# PCIE_APPLICATION register map
Vendor: Texas Instruments
Peripheral module from a debugger description file (folder 66AK2G0x_66AK2G1x).
Registers are 32-bit, access not given, reset 0x0 unless marked. A register's access mark holds for its fields unless they carry their own. Offsets are as the file gives them; lines under a group give offsets from that group; [hi:lo] are bit positions; {n}, {i} and the like mark numbered series; 'fields as' and 'values as' point back to an identical list; <NAME> marks a mode.

## PCIE_APPLICATION
0x00 PCIE_PID ro reset 0x4E330900
  [31:0] REV — TI internal data. Identifies revision of peripheral.
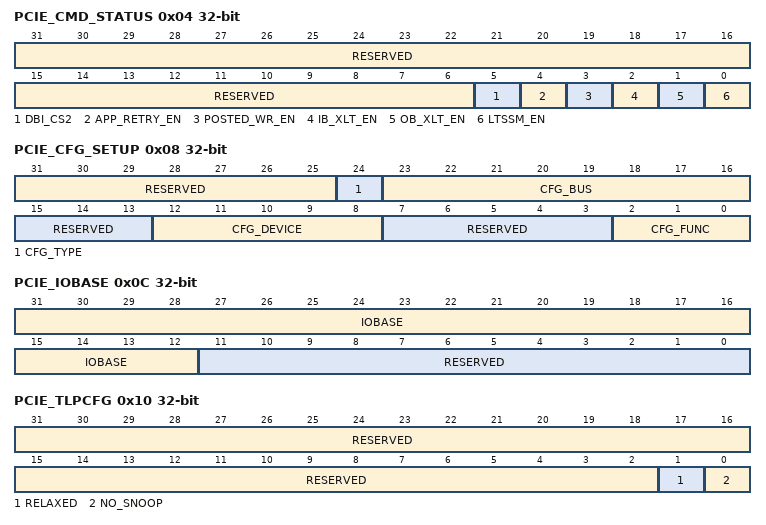
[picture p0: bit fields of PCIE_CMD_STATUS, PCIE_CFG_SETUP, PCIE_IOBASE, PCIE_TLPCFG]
0x04 PCIE_CMD_STATUS access per field
  [31:6] RESERVED ro — Reads return 0 and writes have no effect.
  [5] DBI_CS2 rw — Set to enable writing to BAR mask registers that are overlaid on BAR registers.
  [4] APP_RETRY_EN rw — Application request retry enable. This feature can be used if initialization can take longer than PCIe stipulated time frame.
  [3] POSTED_WR_EN rw — Posted write enable. Default is 0 with all internal bus master writes defaulting to non-posted.
  [2] IB_XLT_EN rw — Inbound address translation enable.
  [1] OB_XLT_EN rw — Outbound address translation enable.
  [0] LTSSM_EN rw — Link training enable.
0x08 PCIE_CFG_SETUP access per field
  [31:25] RESERVED ro — Reads return 0 and writes have no effect.
  [24] CFG_TYPE rw — Configuration type for outbound configuration accesses.
  [23:16] CFG_BUS rw — PCIe bus number for outbound configuration accesses (value = 0-FFh).
  [15:13] RESERVED ro — Reads return 0 and writes have no effect.
  [12:8] CFG_DEVICE rw — PCIe device number for outbound configuration accesses (value = 0-1Fh).
  [7:3] RESERVED ro — Reads return 0 and writes have no effect.
  [2:0] CFG_FUNC rw — PCIe function number for outbound configuration accesses (value = 0-7h).
0x0C PCIE_IOBASE access per field
  [31:12] IOBASE rw — Bits [31-12] of outgoing IO TLP (value = 0-FFFFFh). RC mode only.
  [11:0] RESERVED ro — Reads return 0 and writes have no effect.
0x10 PCIE_TLPCFG access per field
  [31:2] RESERVED ro — Reads return 0 and writes have no effect.
  [1] RELAXED rw — Enable relaxed ordering for all outgoing TLPs.
  [0] NO_SNOOP rw — Enable No Snoop attribute on all outgoing TLPs.
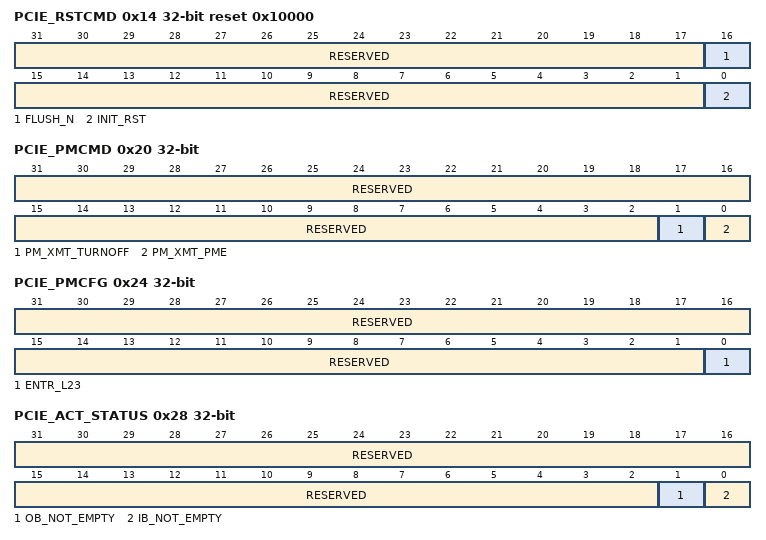
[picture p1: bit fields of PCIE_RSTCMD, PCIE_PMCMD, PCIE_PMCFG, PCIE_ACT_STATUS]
0x14 PCIE_RSTCMD reset 0x10000
  [31:17] RESERVED ro — Reads return 0 and writes have no effect.
  [16] FLUSH_N ro — Bridge flush status. Used to ensure no pending transactions prior to issuing warm reset.
  [15:1] RESERVED ro — Reads return 0 and writes have no effect.
  [0] INIT_RST — Write 1 to initiate a downstream hot reset sequence on downstream. (access W1S)
0x20 PCIE_PMCMD
  [31:2] RESERVED ro — Reads return 0 and writes have no effect.
  [1] PM_XMT_TURNOFF — Write 1 to transmit a PM_TURNOFF message. Reads 0. Applicable in RC mode only. (access W1S)
  [0] PM_XMT_PME — Write 1 to transmit a PM_PME message. Reads 0. Applicable to EP mode only. (access W1S)
0x24 PCIE_PMCFG access per field
  [31:1] RESERVED ro — Reads return 0 and writes have no effect.
  [0] ENTR_L23 rw — Write 1 to enable entry to L2/L3 ready state. Read to check L2/L3 entry readiness. Applicable to RC and EP.
0x28 PCIE_ACT_STATUS ro
  [31:2] RESERVED — Reads return 0 and writes have no effect.
  [1] OB_NOT_EMPTY
  [0] IB_NOT_EMPTY
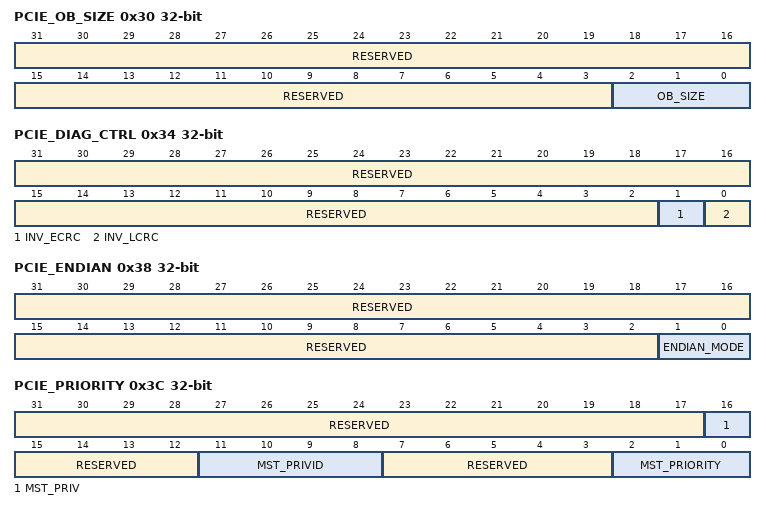
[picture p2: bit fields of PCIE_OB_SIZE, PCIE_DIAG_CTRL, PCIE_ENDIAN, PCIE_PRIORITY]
0x30 PCIE_OB_SIZE access per field
  [31:3] RESERVED ro — Reads return 0 and writes have no effect.
  [2:0] OB_SIZE rw — Set each outbound translation window size. Applicable to RC and EP.
0x34 PCIE_DIAG_CTRL access per field
  [31:2] RESERVED ro — Reads return 0 and writes have no effect.
  [1] INV_ECRC rw — Write 1 to force inversion of LSB of ECRC for the next one packet. It is self cleared when the ECRC error has been injected on one TLP.
  [0] INV_LCRC rw — Write 1 to force inversion of LSB of LCRC for the next one packet. It is self cleared when the LCRC error has been injected on one TLP.
0x38 PCIE_ENDIAN access per field
  [31:2] RESERVED ro — Reads return 0 and writes have no effect.
  [1:0] ENDIAN_MODE rw
0x3C PCIE_PRIORITY access per field
  [31:17] RESERVED ro — Reads return 0 and writes have no effect.
  [16] MST_PRIV rw — Master transaction mode. PCIe transaction needs to be in supervisor mode to access the device registers.
  [15:12] RESERVED ro — Reads return 0 and writes have no effect.
  [11:8] MST_PRIVID ro — Master PRIVID value on master transactions.
  [7:3] RESERVED ro — Reads return 0 and writes have no effect.
  [2:0] MST_PRIORITY rw — Priority level for each inbound transaction on the internal bus master port. 0 is the highest priority level and 7h is the lowest priority level.
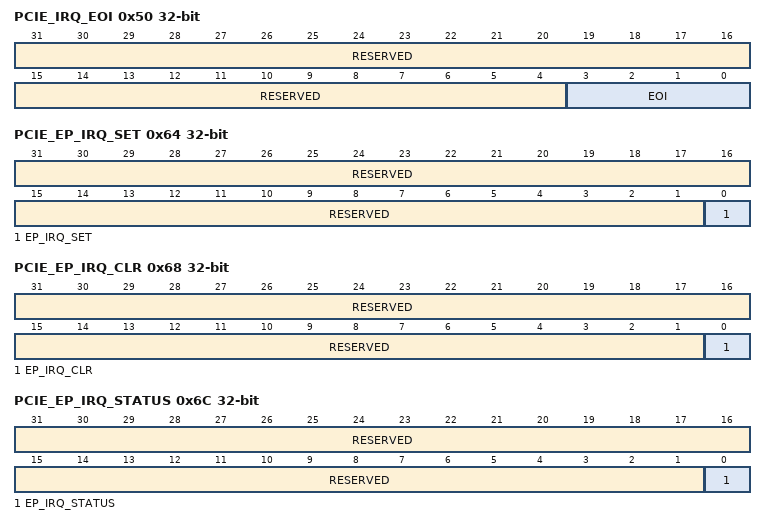
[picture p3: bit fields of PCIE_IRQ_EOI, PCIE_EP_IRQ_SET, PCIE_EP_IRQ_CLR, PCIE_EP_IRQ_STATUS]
0x50 PCIE_IRQ_EOI access per field
  [31:4] RESERVED ro — Reads return 0 and writes have no effect.
  [3:0] EOI wo — EOI for interrupts. Write the interrupt event number to indicate end-of-interrupt for the interrupt events. Write 0 to mark EOI for INTA, 1 for INTB and so on. Please see the for the interrupt event number.
0x54 PCIE_MSI_IRQ wo
  [31:0] MSI_IRQ — This register is written to by the remote device. Writes initiated by an EP over PCIe link that targetPCIE_BAR0 of the RC land to this register if the offset matches. EP should write MSI vector value to this register to generate corresponding MSI Interrupt, such as writing 0x0 to generate MSI_0 interrupt (with vector 0), writing 0x1F to generate MSI_7 interrupt (with vector 31).
0x64 PCIE_EP_IRQ_SET
  [31:1] RESERVED ro — Reads return 0 and writes have no effect.
  [0] EP_IRQ_SET — Write 1 to generate assert interrupt message. If MSI is disabled, legacy interrupt assert message will be generated. On read, a 1 indicates currently asserted interrupt. (access RW1S)
0x68 PCIE_EP_IRQ_CLR
  [31:1] RESERVED ro — Reads return 0 and writes have no effect.
  [0] EP_IRQ_CLR — Write 1 to generate deassert interrupt message. If MSI is disabled, legacy interrupt deassert message will be generated. On read, a 1 indicates currently asserted interrupt. (access RW1C)
0x6C PCIE_EP_IRQ_STATUS ro
  [31:1] RESERVED — Reads return 0 and writes have no effect.
  [0] EP_IRQ_STATUS — Indicates whether interrupt for function 0 is asserted or not.
{0x70+4i} PCIE_GPR{i} rw (i=0..3)
  [31:0] GENERIC{i} — Generic info field {i} (value = 0-FFFFFFFFh).
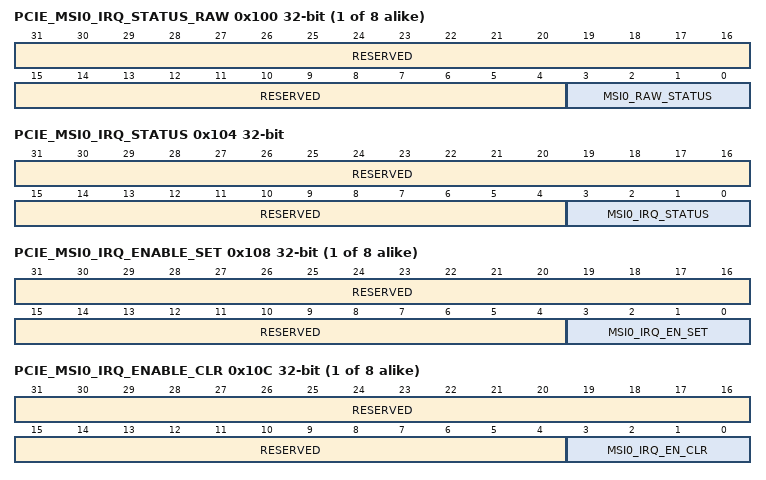
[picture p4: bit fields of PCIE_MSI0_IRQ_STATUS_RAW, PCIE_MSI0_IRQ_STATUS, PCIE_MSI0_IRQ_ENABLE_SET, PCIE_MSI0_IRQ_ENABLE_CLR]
{0x100+0x10*i} PCIE_MSI{i}_IRQ_STATUS_RAW (i=0..7)
  [31:4] RESERVED ro — Reads return 0 and writes have no effect.
  [3:0] MSI{i}_RAW_STATUS — Each bit indicates raw status of MSI vectors ({i+24}, {i+16}, {i+8}, {i}) associated with the bit. Typically, writes to this register are only done for debug purposes. (access RW1S)
0x104 PCIE_MSI0_IRQ_STATUS
  [31:4] RESERVED ro — Reads return 0 and writes have no effect.
  [3:0] MSI0_IRQ_STATUS — Each bit indicates status of MSI vector (24, 16, 8, 0) associated with the bit. Each of the bits can be written with 1 to clear the respective interrupt status bit. (access RW1C)
{0x108+0x10*i} PCIE_MSI{i}_IRQ_ENABLE_SET (i=0..7)
  [31:4] RESERVED ro — Reads return 0 and writes have no effect.
  [3:0] MSI{i}_IRQ_EN_SET — Each bit, when written to, enables the MSI interrupt ({i+24}, {i+16}, {i+8}, {i}) associated with the bit. (access RW1S)
{0x10C+0x10*i} PCIE_MSI{i}_IRQ_ENABLE_CLR (i=0..7)
  [31:4] RESERVED ro — Reads return 0 and writes have no effect.
  [3:0] MSI{i}_IRQ_EN_CLR — Each bit, when written to, disables the MSI interrupt ({i+24}, {i+16}, {i+8}, {i}) associated with the bit. (access RW1C)
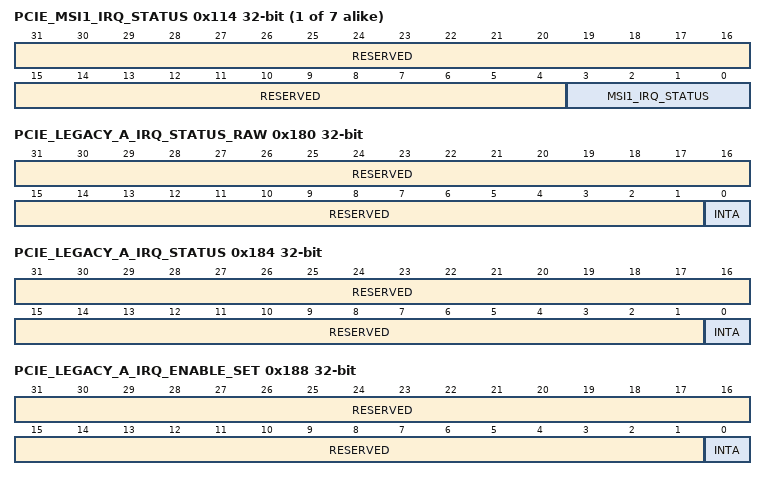
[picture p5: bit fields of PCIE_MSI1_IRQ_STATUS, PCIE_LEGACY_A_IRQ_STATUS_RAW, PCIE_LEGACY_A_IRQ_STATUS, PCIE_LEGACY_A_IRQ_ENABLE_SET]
{0x104+0x10*i} PCIE_MSI{i}_IRQ_STATUS (i=1..7)
  [31:4] RESERVED ro — Reads return 0 and writes have no effect.
  [3:0] MSI{i}_IRQ_STATUS — Each bit indicates status of MSI vector ({i+24}, {i+16}, {i+8}, {i}) associated with the bit. Each of the bits can be written with one to clear the respective interrupt status bit. (access RW1C)
0x180 PCIE_LEGACY_A_IRQ_STATUS_RAW
  [31:1] RESERVED ro — Reads return 0 and writes have no effect.
  [0] INTA — Legacy Interrupt A raw status. RC mode only. (access RW1S)
0x184 PCIE_LEGACY_A_IRQ_STATUS
  [31:1] RESERVED ro — Reads return 0 and writes have no effect.
  [0] INTA — Legacy Interrupt A status. Set when interrupt is active. Write one to clear the interrupt event. RC mode only. (access RW1C)
0x188 PCIE_LEGACY_A_IRQ_ENABLE_SET
  [31:1] RESERVED ro — Reads return 0 and writes have no effect.
  [0] INTA — Legacy Interrupt A enable. Set to enable the interrupt.On read: (access RW1S)
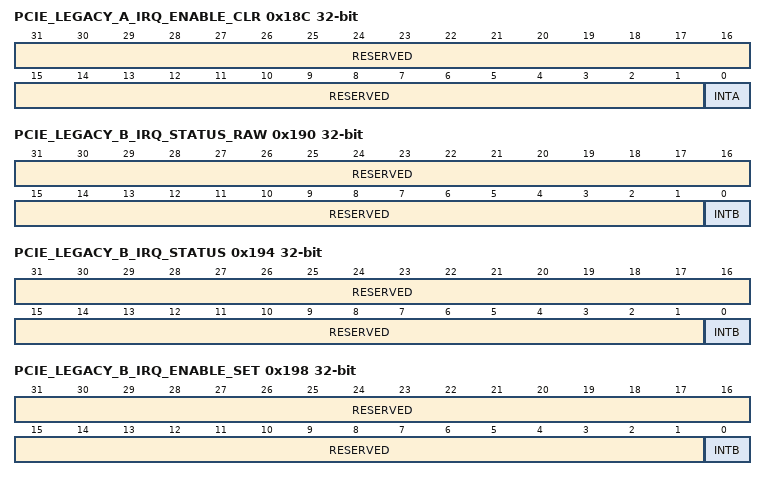
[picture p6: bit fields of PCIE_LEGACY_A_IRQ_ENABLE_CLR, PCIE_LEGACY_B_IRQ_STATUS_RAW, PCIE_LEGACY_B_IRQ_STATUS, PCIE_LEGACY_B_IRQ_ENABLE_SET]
0x18C PCIE_LEGACY_A_IRQ_ENABLE_CLR
  [31:1] RESERVED ro — Reads return 0 and writes have no effect.
  [0] INTA — Legacy Interrupt A disable. Set to disable the interrupt.On read: (access RW1C)
0x190 PCIE_LEGACY_B_IRQ_STATUS_RAW
  [31:1] RESERVED ro — Reads return 0 and writes have no effect.
  [0] INTB — Legacy Interrupt B raw status. RC mode only. (access RW1S)
0x194 PCIE_LEGACY_B_IRQ_STATUS
  [31:1] RESERVED ro — Reads return 0 and writes have no effect.
  [0] INTB — Legacy Interrupt B status. Set when interrupt is active. Write one to clear the interrupt event. RC mode only. (access RW1C)
0x198 PCIE_LEGACY_B_IRQ_ENABLE_SET
  [31:1] RESERVED ro — Reads return 0 and writes have no effect.
  [0] INTB — Legacy Interrupt B enable. Set to enable the interrupt.On read: (access RW1S)
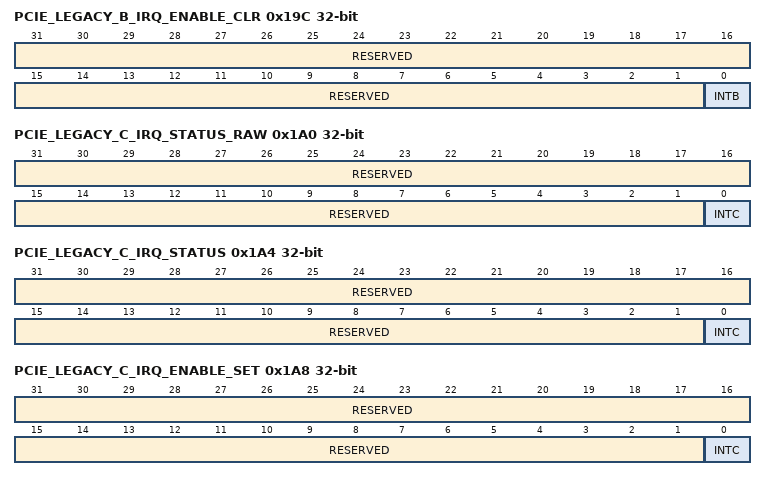
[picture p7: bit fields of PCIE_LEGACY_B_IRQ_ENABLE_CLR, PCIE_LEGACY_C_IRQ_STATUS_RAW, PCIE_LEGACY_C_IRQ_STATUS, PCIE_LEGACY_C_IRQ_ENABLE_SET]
0x19C PCIE_LEGACY_B_IRQ_ENABLE_CLR
  [31:1] RESERVED ro — Reads return 0 and writes have no effect.
  [0] INTB — Legacy Interrupt B disable. Set to disable the interrupt.On read: (access RW1C)
0x1A0 PCIE_LEGACY_C_IRQ_STATUS_RAW
  [31:1] RESERVED ro — Reads return 0 and writes have no effect.
  [0] INTC — Legacy Interrupt C raw status. RC mode only. (access RW1S)
0x1A4 PCIE_LEGACY_C_IRQ_STATUS
  [31:1] RESERVED ro — Reads return 0 and writes have no effect.
  [0] INTC — Legacy Interrupt C status. Set when interrupt is active. Write one to clear the interrupt event. RC mode only. (access RW1C)
0x1A8 PCIE_LEGACY_C_IRQ_ENABLE_SET
  [31:1] RESERVED ro — Reads return 0 and writes have no effect.
  [0] INTC — Legacy Interrupt C enable. Set to enable the interrupt.On read: (access RW1S)
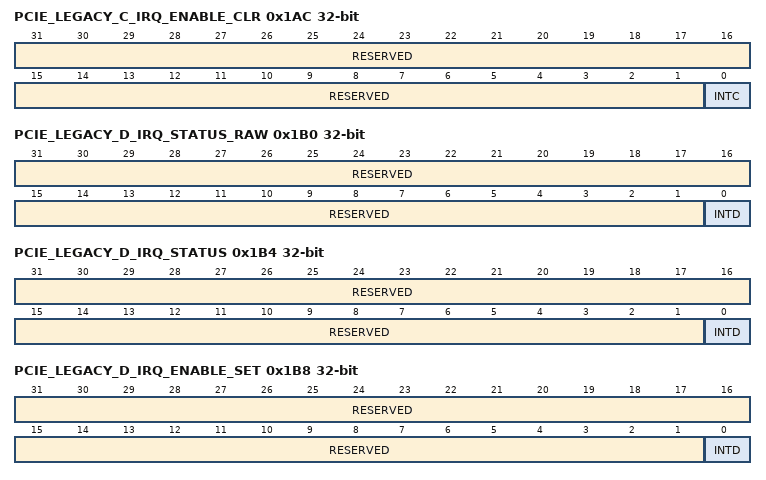
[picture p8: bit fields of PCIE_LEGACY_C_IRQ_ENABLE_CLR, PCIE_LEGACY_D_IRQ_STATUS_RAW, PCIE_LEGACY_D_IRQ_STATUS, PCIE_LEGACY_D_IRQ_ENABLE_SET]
0x1AC PCIE_LEGACY_C_IRQ_ENABLE_CLR
  [31:1] RESERVED ro — Reads return 0 and writes have no effect.
  [0] INTC — Legacy Interrupt C disable. Set to disable the interrupt.On read: (access RW1C)
0x1B0 PCIE_LEGACY_D_IRQ_STATUS_RAW
  [31:1] RESERVED ro — Reads return 0 and writes have no effect.
  [0] INTD — Legacy Interrupt D raw status. RC mode only. (access RW1S)
0x1B4 PCIE_LEGACY_D_IRQ_STATUS
  [31:1] RESERVED ro — Reads return 0 and writes have no effect.
  [0] INTD — Legacy Interrupt D status. Set when interrupt is active. Write one to clear the interrupt event. RC mode only. (access RW1C)
0x1B8 PCIE_LEGACY_D_IRQ_ENABLE_SET
  [31:1] RESERVED ro — Reads return 0 and writes have no effect.
  [0] INTD — Legacy Interrupt D enable. Set to enable the interrupt.On read: (access RW1S)
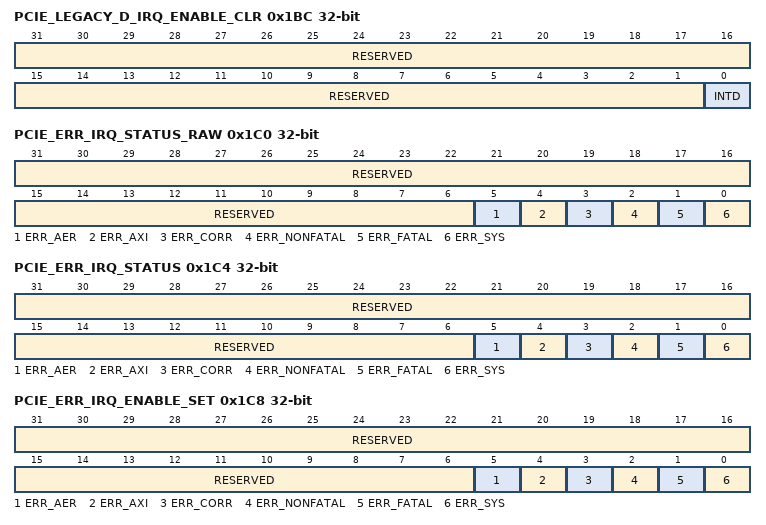
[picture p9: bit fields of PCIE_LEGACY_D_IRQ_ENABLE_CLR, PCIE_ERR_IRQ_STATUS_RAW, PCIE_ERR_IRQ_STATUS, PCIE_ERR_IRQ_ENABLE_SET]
0x1BC PCIE_LEGACY_D_IRQ_ENABLE_CLR
  [31:1] RESERVED ro — Reads return 0 and writes have no effect.
  [0] INTD — Legacy Interrupt D disable. Set to disable the interrupt.On read: (access RW1C)
0x1C0 PCIE_ERR_IRQ_STATUS_RAW
  [31:6] RESERVED ro — Reads return 0 and writes have no effect.
  [5] ERR_AER — ECRC error raw status. (access RW1S)
  [4] ERR_AXI — AXI tag lookup fatal error raw status. (access RW1S)
  [3] ERR_CORR — Correctable error raw status. (access RW1S)
  [2] ERR_NONFATAL — Nonfatal error raw status. (access RW1S)
  [1] ERR_FATAL — Fatal error raw status. (access RW1S)
  [0] ERR_SYS — System error (fatal, nonfatal or correctable error) raw status. (access RW1S)
0x1C4 PCIE_ERR_IRQ_STATUS
  [31:6] RESERVED ro — Reads return 0 and writes have no effect.
  [5] ERR_AER — ECRC error status. (access RW1C)
  [4] ERR_AXI — AXI tag lookup fatal error. (access RW1C)
  [3] ERR_CORR — Correctable error status. (access RW1C)
  [2] ERR_NONFATAL — Nonfatal error status. (access RW1C)
  [1] ERR_FATAL — Fatal error status. (access RW1C)
  [0] ERR_SYS — System Error (fatal, nonfatal or correctable error). (access RW1C)
0x1C8 PCIE_ERR_IRQ_ENABLE_SET
  [31:6] RESERVED ro — Reads return 0 and writes have no effect.
  [5] ERR_AER — ECRC error interrupt enable. Set to enable the interrupt.On read: (access RW1S)
  [4] ERR_AXI — AXI tag lookup fatal error interrupt enable. Set to enable the interrupt.On read: (access RW1S)
  [3] ERR_CORR — Correctable error interrupt enable. Set to enable the interrupt.On read: (access RW1S)
  [2] ERR_NONFATAL — Nonfatal error interrupt enable. Set to enable the interrupt.On read: (access RW1S)
  [1] ERR_FATAL — Fatal error interrupt enable. Set to enable the interrupt.On read: (access RW1S)
  [0] ERR_SYS — System Error (fatal, nonfatal or correctable error) interrupt enable. Set to enable the interrupt.On read: (access RW1S)
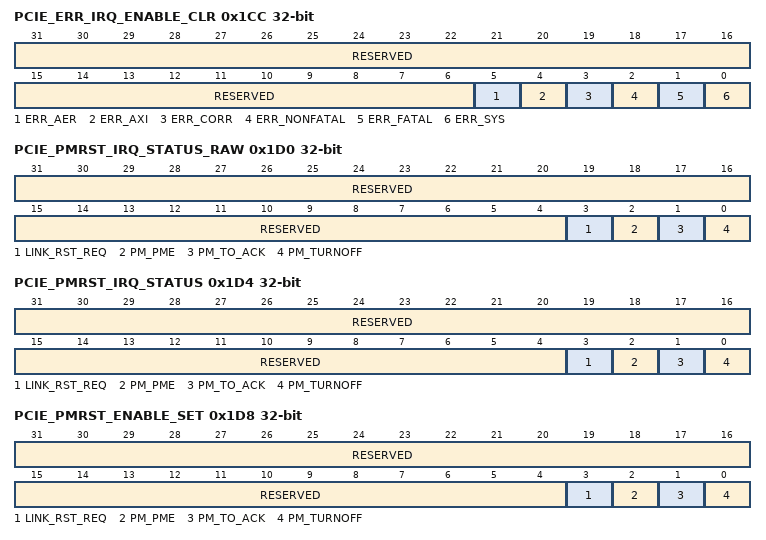
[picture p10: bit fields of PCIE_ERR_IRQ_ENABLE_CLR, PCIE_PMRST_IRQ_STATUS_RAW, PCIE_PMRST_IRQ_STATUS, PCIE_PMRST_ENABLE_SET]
0x1CC PCIE_ERR_IRQ_ENABLE_CLR
  [31:6] RESERVED ro — Reads return 0 and writes have no effect.
  [5] ERR_AER — ECRC error interrupt disable. Set to disable the interrupt.On read: (access RW1C)
  [4] ERR_AXI — AXI tag lookup fatal error interrupt disable. Set to disable the interrupt.On read: (access RW1C)
  [3] ERR_CORR — Correctable error interrupt disable. Set to disable the interrupt.On read: (access RW1C)
  [2] ERR_NONFATAL — Nonfatal error interrupt disable. Set to disable the interrupt.On read: (access RW1C)
  [1] ERR_FATAL — Fatal error interrupt disable. Set to disable the interrupt.On read: (access RW1C)
  [0] ERR_SYS — System error (fatal, nonfatal or correctable error) interrupt disable. Set to disable the interrupt.On read: (access RW1C)
0x1D0 PCIE_PMRST_IRQ_STATUS_RAW
  [31:4] RESERVED ro — Reads return 0 and writes have no effect.
  [3] LINK_RST_REQ — Link Request Reset interrupt raw status. (access RW1S)
  [2] PM_PME — Power management PME message received interrupt raw status. (access RW1S)
  [1] PM_TO_ACK — Power management ACK received interrupt raw status. (access RW1S)
  [0] PM_TURNOFF — Power management turnoff message received raw status. (access RW1S)
0x1D4 PCIE_PMRST_IRQ_STATUS
  [31:4] RESERVED ro — Reads return 0 and writes have no effect.
  [3] LINK_RST_REQ — Link request reset interrupt status. (access RW1C)
  [2] PM_PME — Power management PME message received interrupt status. (access RW1C)
  [1] PM_TO_ACK — Power management ACK received interrupt status. (access RW1C)
  [0] PM_TURNOFF — Power management turnoff message received status. (access RW1C)
0x1D8 PCIE_PMRST_ENABLE_SET
  [31:4] RESERVED ro — Reads return 0 and writes have no effect.
  [3] LINK_RST_REQ — Link request reset interrupt enable. Set to enable the interrupt.On read: (access RW1S)
  [2] PM_PME — Power management PME message received interrupt enable. Set to enable the interrupt.On read: (access RW1S)
  [1] PM_TO_ACK — Power management ACK received interrupt enable. Set to enable the interrupt.On read: (access RW1S)
  [0] PM_TURNOFF — Power management turnoff message received enable. Set to enable the interrupt.On read: (access RW1S)
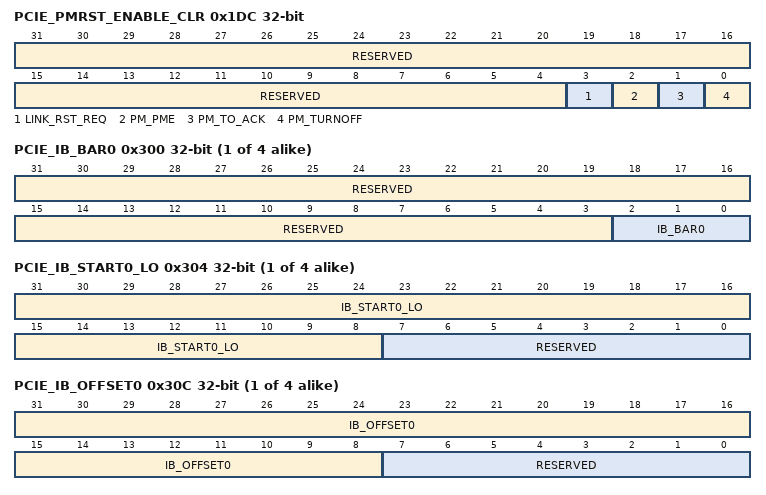
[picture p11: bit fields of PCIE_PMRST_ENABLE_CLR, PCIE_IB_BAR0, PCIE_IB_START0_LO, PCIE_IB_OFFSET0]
0x1DC PCIE_PMRST_ENABLE_CLR
  [31:4] RESERVED ro — Reads return 0 and writes have no effect.
  [3] LINK_RST_REQ — Link Request Reset interrupt disable. Set to disable the interrupt.On read: (access RW1C)
  [2] PM_PME — Power management PME message received interrupt disable. Set to disable the interrupt.On read: (access RW1C)
  [1] PM_TO_ACK — Power management ACK received interrupt disable. Set to disable the interrupt.On read: (access RW1C)
  [0] PM_TURNOFF — Power management Turnoff message received disable. Set to disable the interrupt.On read: (access RW1C)
{0x300+0x10*i} PCIE_IB_BAR{i} access per field (i=0..3)
  [31:3] RESERVED ro — Reads return 0 and writes have no effect.
  [2:0] IB_BAR{i} rw — BAR number to match for inbound translation region {i}.
{0x304+0x10*i} PCIE_IB_START{i}_LO access per field (i=0..3)
  [31:8] IB_START{i}_LO rw — Start address bits [31-8] for inbound translation region {i}.
  [7:0] RESERVED ro — Reads return 0 and writes have no effect.
{0x308+0x10*i} PCIE_IB_START{i}_HI rw (i=0..3)
  [31:0] IB_START{i}_HI — Start address bits [63-32] for inbound translation region {i}.
{0x30C+0x10*i} PCIE_IB_OFFSET{i} access per field (i=0..3)
  [31:8] IB_OFFSET{i} rw — Offset address bits [31-8] for inbound translation region {i}.
  [7:0] RESERVED ro — Reads return 0 and writes have no effect.
